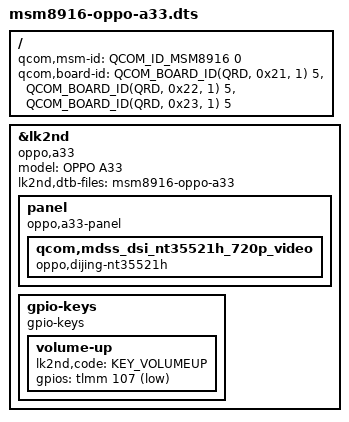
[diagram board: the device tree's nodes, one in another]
// SPDX-License-Identifier: BSD-3-Clause

#include <skeleton64.dtsi>
#include <lk2nd.dtsi>

/ {
	qcom,msm-id = <QCOM_ID_MSM8916 0>;
	qcom,board-id = <QCOM_BOARD_ID(QRD, 0x21, 1) 5>,
		<QCOM_BOARD_ID(QRD, 0x22, 1) 5>,
		<QCOM_BOARD_ID(QRD, 0x23, 1) 5>;
};

&lk2nd {
	model = "OPPO A33";
	compatible = "oppo,a33", "oppo,ql790";
	lk2nd,dtb-files = "msm8916-oppo-a33";

	panel {
		compatible = "oppo,a33-panel", "lk2nd,panel";

		qcom,mdss_dsi_nt35521h_720p_video {
			compatible = "oppo,dijing-nt35521h";
		};
	};

	gpio-keys {
		compatible = "gpio-keys";

		volume-up {
			lk2nd,code = <KEY_VOLUMEUP>;
			gpios = <&tlmm 107 (GPIO_ACTIVE_LOW | GPIO_PULL_UP)>;
		};
	};
};
